# wsoc_descr_fifo_secure register map
Vendor: Texas Instruments
Peripheral module from a debugger description file (folder CC35X1).
Registers are 32-bit, access per field, no defined reset value unless marked. A register's access mark holds for its fields unless they carry their own. Offsets are as the file gives them; lines under a group give offsets from that group; [hi:lo] are bit positions; {n}, {i} and the like mark numbered series; 'fields as' and 'values as' point back to an identical list; <NAME> marks a mode.

## wsoc_descr_fifo_secure
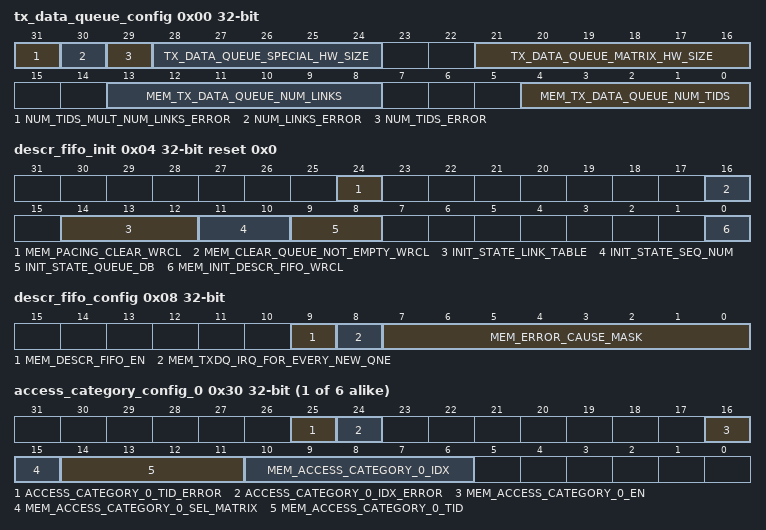
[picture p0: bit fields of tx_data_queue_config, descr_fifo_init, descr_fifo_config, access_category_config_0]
0x00 tx_data_queue_config
  [31] NUM_TIDS_MULT_NUM_LINKS_ERROR ro
  [30] NUM_LINKS_ERROR ro
  [29] NUM_TIDS_ERROR ro
  [28:24] TX_DATA_QUEUE_SPECIAL_HW_SIZE ro — size of TX_DATA_QUEUE_SPECIAL (hard coded in range of 1..32) used to validate settings of MEM_ACCESS_CATEGORY_*_IDX when MEM_ACCESS_CATEGORY_*_SEL_MATRIX=0
  [21:16] TX_DATA_QUEUE_MATRIX_HW_SIZE ro — size of TX_DATA_QUEUE_MATRIX queue (hard coded in range of 1..32) MATRIX_HW_SIZE = NUM_TIDs(rows)*NUM_LINKS(columns)
  [13:8] MEM_TX_DATA_QUEUE_NUM_LINKS rw — number of COLUMNS in matrix (valid values 1..TX_DATA_QUEUE_MATRIX_HW_SIZE)
  [4:0] MEM_TX_DATA_QUEUE_NUM_TIDS rw — number of ROWS in matrix (valid values 1..9)
0x04 descr_fifo_init reset 0x0
  [24] MEM_PACING_CLEAR_WRCL wo — command to clear all pacing flops (timeout_cnt and queue_len_thr_pass)
  [16] MEM_CLEAR_QUEUE_NOT_EMPTY_WRCL wo — command to clear all queue_not_empty bits to 0
  [14:12] INIT_STATE_LINK_TABLE ro — init state of LinkTable 000 = idle 001 = init descriptor 010 = init sub-descriptor 100 = init done
  [11:10] INIT_STATE_SEQ_NUM ro — init state of Sequence_Number RAM 00 = idle 01 = init seq_num 10 = init done
  [9:8] INIT_STATE_QUEUE_DB ro — init state of QueueDB 00 = idle 01 = init qdb 10 = init done
  [0] MEM_INIT_DESCR_FIFO_WRCL wo — command to start init of queue_db + link_table + seq_num memories
0x08 descr_fifo_config
  [9] MEM_DESCR_FIFO_EN rw — 1 - descr fifo is enabled. Requests are allowed. 0 - descr fifo is disabled. Requests will return req_while_not_enabled_error (IRQ). default is 0
  [8] MEM_TXDQ_IRQ_FOR_EVERY_NEW_QNE rw — 1 - interrupt for every new "not_empty" for any of TX Data queues 0 - interrupt for every new "not_empty" for a TX Data queue that is either not-AC-selected or AC-selected-but-not-qv
  [7:0] MEM_ERROR_CAUSE_MASK rw — mask bits for error irq cause. 0 - cause bit enabled 1 - cause bit masked/disabled cause bits: [6] join_source_eq_target_error [5] not_null_error [4] descr_out_of_range_error [3] seq_num_block_error [2] unsupported_cmd_error [1] mcmd_error [0] address_error
{0xC+4i} queue_not_empty_status_{i} rw reset 0x0 (i=1..4)
  [31:0] MEM_QUEUE_NOT_EMPTY_{i}_WROPT — backup and restore of "non-matrix" queues
0x20 txd_queue_not_empty_status_1 rw reset 0x0
  [31:0] MEM_TX_DATA_QUEUE_NOT_EMPTY_1_WROPT
0x24 txd_queue_not_empty_status_2 reset 0x0
  [23:0] MEM_TX_DATA_QUEUE_NOT_EMPTY_2_WROPT rw
0x28 txd_queue_not_empty_status_3 reset 0x0
  [15:0] MEM_TX_DATA_QUEUE_NOT_EMPTY_3_WROPT rw
{0x30+4i} access_category_config_{i} (i=0..5)
  [25] ACCESS_CATEGORY_{i}_TID_ERROR ro — 0 = configuration OK 1 = configuration error when SEL_MATRIX=1: error when MEM_ACCESS_CATEGORY_0_TID >= MEM_TX_DATA_QUEUE_NUM_TIDS when SEL_MATRIX=0: error is always 0 since MEM_ACCESS_CATEGORY_0_TID is not used
  [24] ACCESS_CATEGORY_{i}_IDX_ERROR ro — 0 = configuration OK 1 = configuration error when SEL_MATRIX=1: error when MEM_ACCESS_CATEGORY_0_IDX >= MEM_TX_DATA_QUEUE_NUM_LINKS when SEL_MATRIX=0: error when MEM_ACCESS_CATEGORY_0_IDX >= TX_DATA_QUEUE_SPECIAL_SIZE
  [16] MEM_ACCESS_CATEGORY_{i}_EN rw — enable this access_category: 0 : disable 1 : enable
  [15] MEM_ACCESS_CATEGORY_{i}_SEL_MATRIX rw — select to which TX_DATA_QUEUE this access_category is mapped: 1 : this accesss_category is mapped to MATRIX, indexed by TID and IDX fields 0 : this accesss_category is mapped to SPECIAL, indexed by IDX field
  [14:11] MEM_ACCESS_CATEGORY_{i}_TID rw — when SEL_MATRIX=1: .....TID select row from TX_DATA_QUEUE_matrix .....valid values: 0 to MEM_TX_DATA_QUEUE_NUM_TIDS-1 when SEL_MATRIX=0: .....not used.
  [10:6] MEM_ACCESS_CATEGORY_{i}_IDX rw — when SEL_MATRIX=1: ...IDX select column from TX_DATA_QUEUE_matrix ...valid values: 0 to MEM_TX_DATA_QUEUE_NUM_LINKS-1 when SEL_MATRIX=0: ...IDX select queue from TX_DATA_QUEUE_Special ...valid values: 0 to TX_DATA_QUEUE_SPECIAL_SIZE-1
0x48 tx_ssl_sw_fifo_qne_mask_irq rw reset 0x0
  [31:0] MEM_TX_SSL_SW_FIFO_QNE_MASK_IRQ — mask of queue_not_empty_tx_ssl_sw_fifo going to IRQ 0 - not masked 1 - masked, queue_not_empty forced to 0
0x50 rx_ssl_nab_fifo_qne_mask_irq rw reset 0x0
  [31:0] MEM_RX_SSL_NAB_FIFO_QNE_MASK_IRQ — mask of queue_not_empty_rx_ssl_nab_fifo going to IRQ 0 - not masked 1 - masked, queue_not_empty forced to 0
0x54 rx_ssl_nab_fifo_qne_mask_nab rw reset 0x0
  [31:0] MEM_RX_SSL_NAB_FIFO_QNE_MASK_NAB — mask of queue_not_empty_rx_ssl_nab_fifo going to NAB 0 - not masked 1 - masked, queue_not_empty forced to 0
0x58 rx_ssl_nab_fifo_qne_status_masked ro reset 0x0
  [31:0] RX_SSL_NAB_FIFO_QNE_MASKED — queue_not_empty vector of rx_ssl_nab_fifo MASKED = RX_SSL_NAB_FIFO_QNE after mask with MEM_RX_SSL_NAB_FIFO_QNE_MASK_IRQ
0x5C rx_ssl_nab_fifo_qne_status_raw ro reset 0x0
  [31:0] RX_SSL_NAB_FIFO_QNE — queue_not_empty vector of rx_ssl_nab_fifo RAW version (before mask)
0x70 tx_ssl_sw_fifo_qne_status ro reset 0x0
  [31:0] TX_SSL_SW_FIFO_QNE — queue_not_empty vector of tx_ssl_sw_fifo
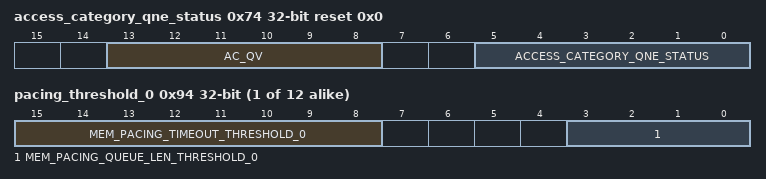
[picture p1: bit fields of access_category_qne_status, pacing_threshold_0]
0x74 access_category_qne_status ro reset 0x0
  [13:8] AC_QV — queue_valid vector of access_category 5..0 comming from pmac
  [5:0] ACCESS_CATEGORY_QNE_STATUS — queue_not_empty vector of access_category 5..0
0x80 descr_fifo_error_status_1 rw
  [31:0] DESCR_FIFO_ERROR_STATUS_1_WROPT — [31:28] descrf_masterid[3:0] - see masterid mapping below [27:15] descrf_mdata[12:0] .....[14] descrf_mcmd[0] (1=WR ; 0=RD) ..[13:0] descrf_maddr[15:2] NOTE: this register has common sticky bit together with DESCR_FIFO_ERROR_STATUS_2_WROPT masterid mapping: 0 - mcu 1 - pmac_ctrl 2 - pmac_data 3 - nab_rx 4 - nab_tx 5 - crypto mcu 6 - hdi 7 - mmu 8 - rs232 9 - phy 10 - top 11 - app 12 - crypto dma
0x84 descr_fifo_error_status_2
  [18:0] DESCR_FIFO_ERROR_STATUS_2_WROPT rw — sources of address_error: [18] txdq_special_addr_error [17] access_category_num_error [16] ac_static_error [15] ac_not_enabled_error [14] txdq_matrix_addr_error [13] txdq_addr_error_num_tids [12] txdq_addr_error_num_links [11] matrix_static_error [10] num_tids_error [ 9] num_links_error [ 8] num_tids_mult_num_links_error irq error cause bits after mask [7] req_while_not_enabled_error [6] join_source_eq_target_error [5] not_null_error [4] descr_out_of_range_error [3] seq_num_block_error [2] unsupported_cmd_error [1] mcmd_error [0] address_error NOTE: this register has common sticky bit together with DESCR_FIFO_ERROR_STATUS_1_WROPT
0x90 pacing_config_general
  [11:0] MEM_PACING_EN rw — Enable Pacing for queues that includes pacing mechanism: PACING #0 - RX_PMAC_COMPLETE PACING #1 - TX_PMAC_EXCHANGE PACING #2 - RX_NAB_DONE PACING #3 - TX_SSL_SW_FIFO (group with mask per queue) PACING #4 - SECURITY_FIFO[1] IPSEC_TX_RESULT PACING #5 - SECURITY_FIFO[3] IPSEC_RX_RESULT PACING #6 - SECURITY_FIFO[5] L2AES_TX_RESULT PACING #7 - SECURITY_FIFO[7] L2AES_RX_RESULT PACING #8 - SW_USAGE[0] PACING #9 - SW_USAGE[1] PACING #10 - SW_USAGE[2] PACING #11 - SUB_DESC_FREE_LIST
{0x94+4i} pacing_threshold_{i} (i=0..11)
  [15:8] MEM_PACING_TIMEOUT_THRESHOLD_{i} rw — timeout threshold in steps of 32 usec
  [3:0] MEM_PACING_QUEUE_LEN_THRESHOLD_{i} rw — threshold for queue_len (values 1..15) set pacing irq if queue_len >= threshold (do not use threshold=0, it will set an irq if pacing is enabled)
0xD0 descr_fifo_spare_1 rw
  [31:0] MEM_DESCR_FIFO_SPARE_1
0x300 sequence_number_ram reset 0x0 — Two Port Async MEM 28x24 Stores TX Data Queues (Special (24) and Matrix (32)) sequence nubmer (12b). Each entry contains two sequence numbers ({2n+1,2n}) By default First 32 entries are allocated for Matrix and last 24 entries are allocated for Special.
  [23:0] MEM_SEQ_NUM_36C_WRMEM rw — SEQUENCE_NUMBER memory access memory for 56 x seq_num ; 12 bit per seq_num implement in 28 lines , two seq_num per line: [11:00] seq_num even [23:12] seq_num odd
0x400 queue_db_ram reset 0x0 — Two Port Async MEM 128x27 Stores queue's head (9b), tail (9b) and length (9b). Up to 128 queues are supported.
  [26:0] MEM_QUEUE_DB_5FC_WRMEM rw — QUEUE_DB memory access [08:00] head [17:09] tail [26:18] queue_len
0x800 link_table_ram reset 0x0 — Single Port Sync RAM 512x13 Stores desc/sud ID (9b) and related Queue Type (4b) Up to 511 desc/sud supported (last entry contains NULL)
  [12:0] MEM_LINK_TABLE_FFC_WRMEMP rw — LINK_TABLE memory access [08:00] descriptor [12:09] queue_type
